# f28004x_gpio_ctrl_regs register map
Vendor: Texas Instruments
Peripheral module from a debugger description file (folder C2000).
Address unit: 16 bits
Registers are 32-bit, read-write, no defined reset value unless marked. A register's access mark holds for its fields unless they carry their own. Offsets are as the file gives them; lines under a group give offsets from that group; [hi:lo] are bit positions; {n}, {i} and the like mark numbered series; 'fields as' and 'values as' point back to an identical list; <NAME> marks a mode.

## GPIO_CTRL_REGS — GPIO CTRL Registers
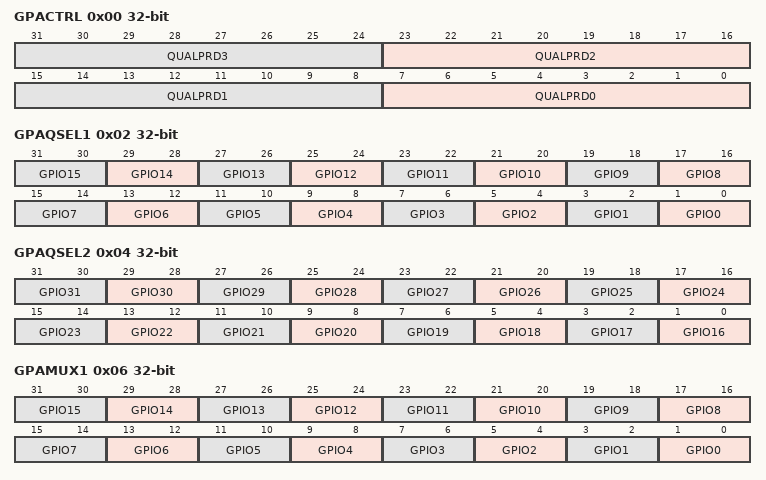
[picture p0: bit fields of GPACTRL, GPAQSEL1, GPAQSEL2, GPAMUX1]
0x00 GPACTRL — GPIO A Qualification Sampling Period (GPIO0 to GPIO31)
  [8n+7:8n] QUALPRD{n} (n=0..3) — Qualification sampling period for GPIO{8n} to GPIO{8n+7}
0x02 GPAQSEL1 — GPIO A Qualification Type (GPIO0 to GPIO15)
  [2n+1:2n] GPIO{n} (n=0..15) — Select input qualification type for GPIO{n}
0x04 GPAQSEL2 — GPIO A Qualification Type (GPIO16 to GPIO31)
  [2n-31:2n-32] GPIO{n} (n=16..31) — Select input qualification type for GPIO{n}
0x06 GPAMUX1 — GPIO A Peripheral Mux (GPIO0 to GPIO15)
  [2n+1:2n] GPIO{n} (n=0..15) — Defines pin-muxing selection for GPIO{n}
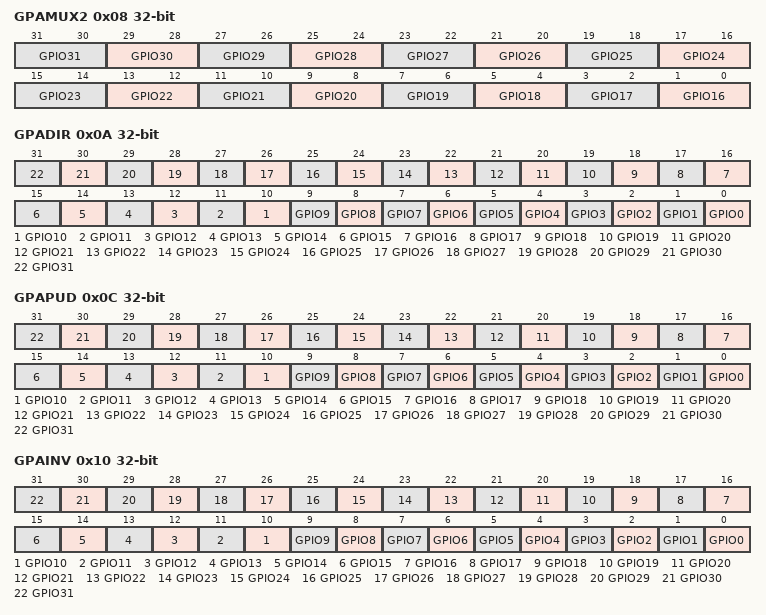
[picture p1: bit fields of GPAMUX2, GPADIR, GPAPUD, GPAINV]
0x08 GPAMUX2 — GPIO A Peripheral Mux (GPIO16 to GPIO31)
  [2n-31:2n-32] GPIO{n} (n=16..31) — Defines pin-muxing selection for GPIO{n}
0x0A GPADIR — GPIO A Direction (GPIO0 to GPIO31)
  [n] GPIO{n} (n=0..31) — Defines direction for this pin in GPIO mode
0x0C GPAPUD — GPIO A Pull-Up Disable (GPIO0 to GPIO31)
  [n] GPIO{n} (n=0..31) — Pull-Up Disable control for this pin
0x10 GPAINV — GPIO A Input Inversion (GPIO0 to GPIO31)
  [n] GPIO{n} (n=0..31) — Input inversion control for this pin
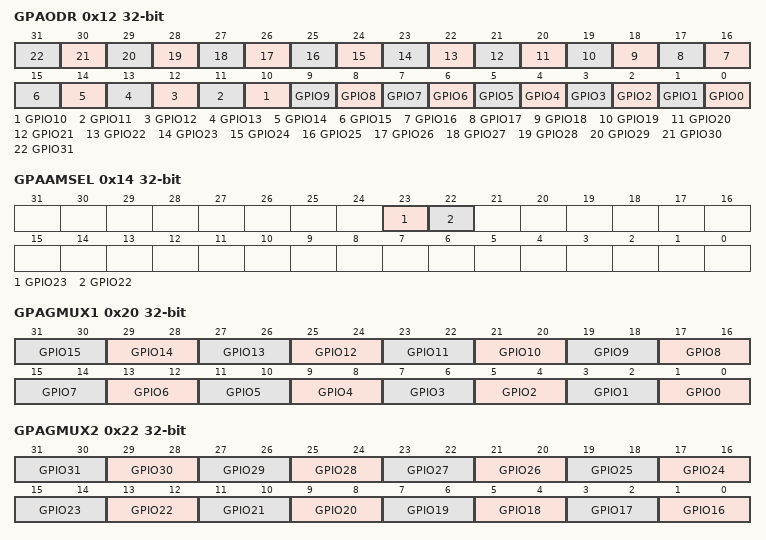
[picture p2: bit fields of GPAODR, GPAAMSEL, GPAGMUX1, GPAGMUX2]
0x12 GPAODR — GPIO A Open Drain Output Mode (GPIO0 to GPIO31)
  [n] GPIO{n} (n=0..31) — Output Open-Drain control for this pin
0x14 GPAAMSEL — GPIO A Analog Mode Select (GPIO0 to GPIO31)
  [23] GPIO23 — Analog Mode select for this pin
  [22] GPIO22 — Analog Mode select for this pin
0x20 GPAGMUX1 — GPIO A Peripheral Group Mux (GPIO0 to GPIO15)
  fields as GPAMUX1
0x22 GPAGMUX2 — GPIO A Peripheral Group Mux (GPIO16 to GPIO31)
  fields as GPAMUX2
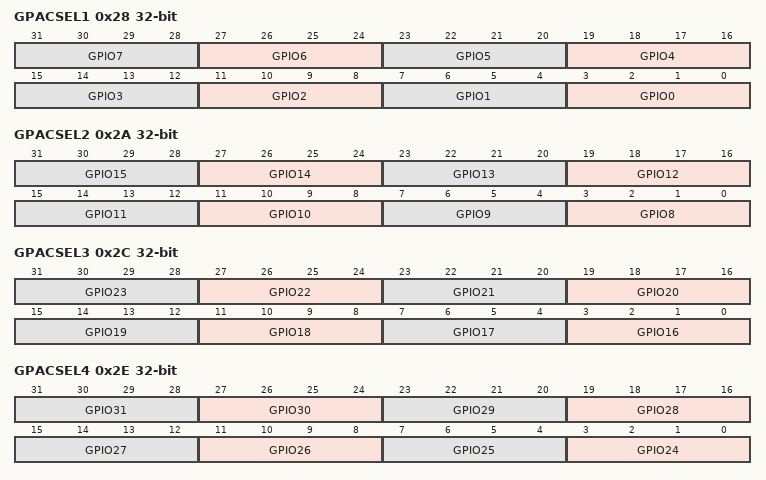
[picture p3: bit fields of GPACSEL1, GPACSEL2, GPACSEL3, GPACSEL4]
0x28 GPACSEL1 — GPIO A Master Core Select (GPIO0 to GPIO7)
  [4n+3:4n] GPIO{n} (n=0..7) — GPIO{n} Master CPU Select
0x2A GPACSEL2 — GPIO A Master Core Select (GPIO8 to GPIO15)
  [4n-29:4n-32] GPIO{n} (n=8..15) — GPIO{n} Master CPU Select
0x2C GPACSEL3 — GPIO A Master Core Select (GPIO16 to GPIO23)
  [4n-61:4n-64] GPIO{n} (n=16..23) — GPIO{n} Master CPU Select
0x2E GPACSEL4 — GPIO A Master Core Select (GPIO24 to GPIO31)
  [4n-93:4n-96] GPIO{n} (n=24..31) — GPIO{n} Master CPU Select
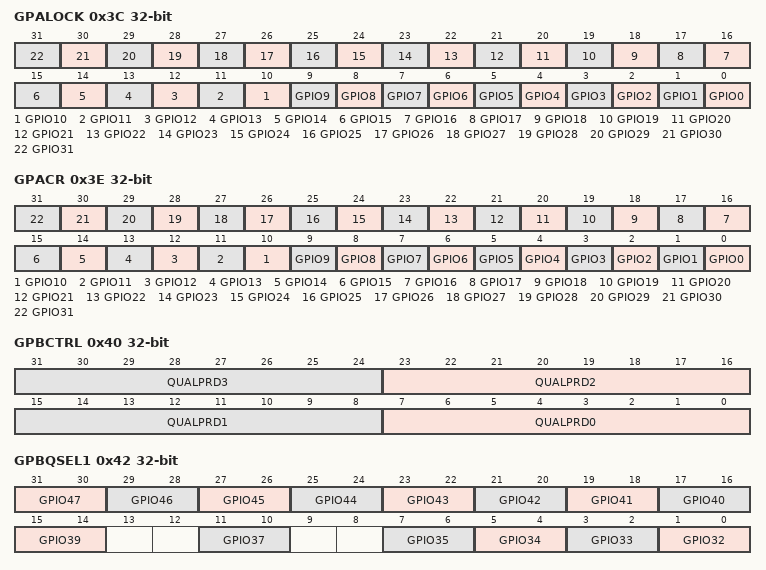
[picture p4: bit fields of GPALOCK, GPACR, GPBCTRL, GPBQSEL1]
0x3C GPALOCK — GPIO A Lock Register (GPIO0 to GPIO31)
  [n] GPIO{n} (n=0..31) — Configuration Lock bit for this pin
0x3E GPACR access not given — GPIO A Lock Commit Register (GPIO0 to GPIO31)
  [n] GPIO{n} (n=0..31) — Configuration lock commit bit for this pin (access R/SOnce)
0x40 GPBCTRL — GPIO B Qualification Sampling Period (GPIO32 to GPIO63)
  [8n+7:8n] QUALPRD{n} (n=0..3) — Qualification sampling period for GPIO{8n+32} to GPIO{8n+39}
0x42 GPBQSEL1 — GPIO B Qualification Type (GPIO32 to GPIO47)
  [2n-63:2n-64] GPIO{n} (n=39..47) — Select input qualification type for GPIO{n}
  [11:10] GPIO37 — Select input qualification type for GPIO37
  [2n-63:2n-64] GPIO{n} (n=32..35) — Select input qualification type for GPIO{n}
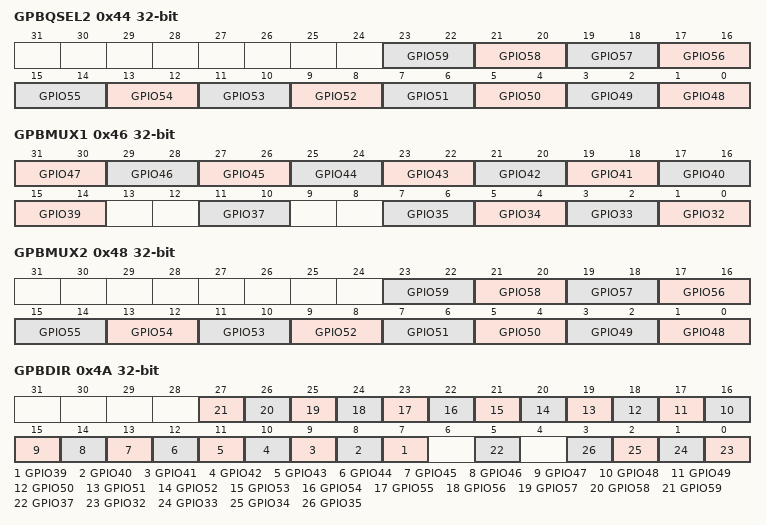
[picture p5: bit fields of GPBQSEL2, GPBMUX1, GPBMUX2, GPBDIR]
0x44 GPBQSEL2 — GPIO B Qualification Type (GPIO48 to GPIO63)
  [2n-95:2n-96] GPIO{n} (n=48..59) — Select input qualification type for GPIO{n}
0x46 GPBMUX1 — GPIO B Peripheral Mux (GPIO32 to GPIO47)
  [2n-63:2n-64] GPIO{n} (n=39..47) — Defines pin-muxing selection for GPIO{n}
  [11:10] GPIO37 — Defines pin-muxing selection for GPIO37
  [2n-63:2n-64] GPIO{n} (n=32..35) — Defines pin-muxing selection for GPIO{n}
0x48 GPBMUX2 — GPIO B Peripheral Mux (GPIO48 to GPIO63)
  [2n-95:2n-96] GPIO{n} (n=48..59) — Defines pin-muxing selection for GPIO{n}
0x4A GPBDIR — GPIO B Direction (GPIO32 to GPIO63)
  [n-32] GPIO{n} (n=39..59) — Defines direction for this pin in GPIO mode
  [5] GPIO37 — Defines direction for this pin in GPIO mode
  [n-32] GPIO{n} (n=32..35) — Defines direction for this pin in GPIO mode
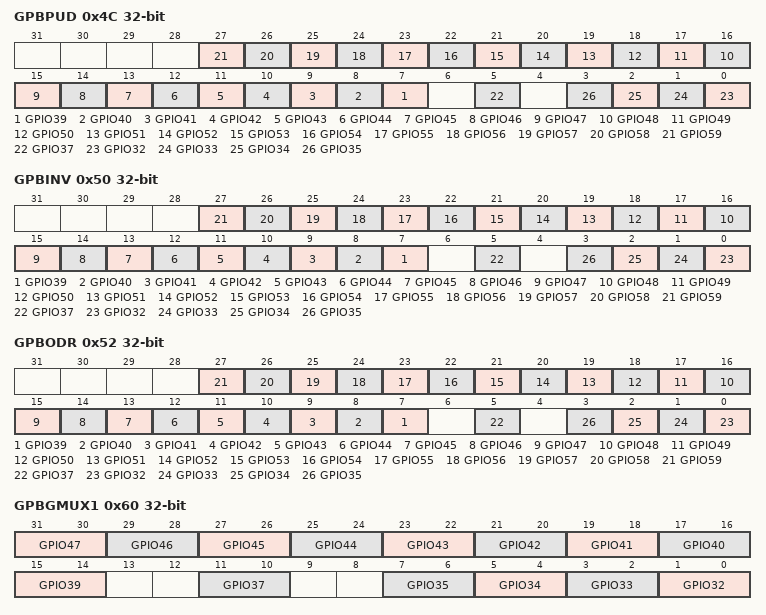
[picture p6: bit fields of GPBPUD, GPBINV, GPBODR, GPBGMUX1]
0x4C GPBPUD — GPIO B Pull-Up Disable (GPIO32 to GPIO63)
  [n-32] GPIO{n} (n=39..59) — Pull-Up Disable control for this pin
  [5] GPIO37 — Pull-Up Disable control for this pin
  [n-32] GPIO{n} (n=32..35) — Pull-Up Disable control for this pin
0x50 GPBINV — GPIO B Input Inversion (GPIO32 to GPIO63)
  [n-32] GPIO{n} (n=39..59) — Input inversion control for this pin
  [5] GPIO37 — Input inversion control for this pin
  [n-32] GPIO{n} (n=32..35) — Input inversion control for this pin
0x52 GPBODR — GPIO B Open Drain Output Mode (GPIO32 to GPIO63)
  [n-32] GPIO{n} (n=39..59) — Output Open-Drain control for this pin
  [5] GPIO37 — Output Open-Drain control for this pin
  [n-32] GPIO{n} (n=32..35) — Output Open-Drain control for this pin
0x60 GPBGMUX1 — GPIO B Peripheral Group Mux (GPIO32 to GPIO47)
  fields as GPBMUX1
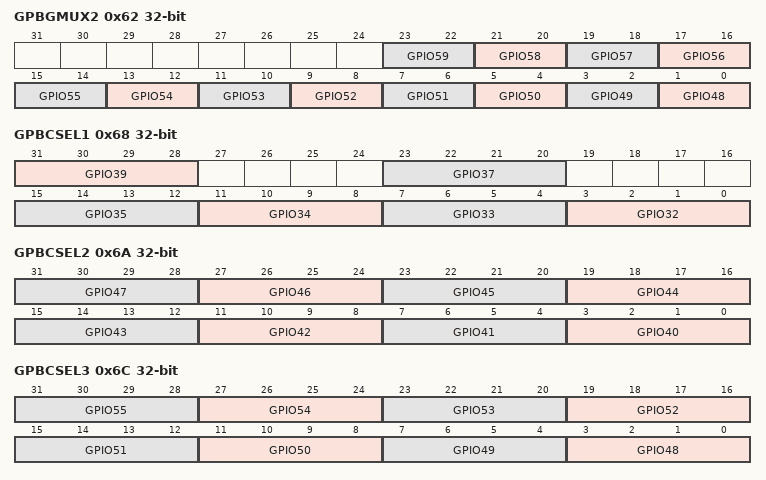
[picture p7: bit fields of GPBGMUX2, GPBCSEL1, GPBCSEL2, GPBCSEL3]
0x62 GPBGMUX2 — GPIO B Peripheral Group Mux (GPIO48 to GPIO63)
  fields as GPBMUX2
0x68 GPBCSEL1 — GPIO B Master Core Select (GPIO32 to GPIO39)
  [31:28] GPIO39 — GPIO39 Master CPU Select
  [23:20] GPIO37 — GPIO37 Master CPU Select
  [4n-125:4n-128] GPIO{n} (n=32..35) — GPIO{n} Master CPU Select
0x6A GPBCSEL2 — GPIO B Master Core Select (GPIO40 to GPIO47)
  [4n-157:4n-160] GPIO{n} (n=40..47) — GPIO{n} Master CPU Select
0x6C GPBCSEL3 — GPIO B Master Core Select (GPIO48 to GPIO55)
  [4n-189:4n-192] GPIO{n} (n=48..55) — GPIO{n} Master CPU Select
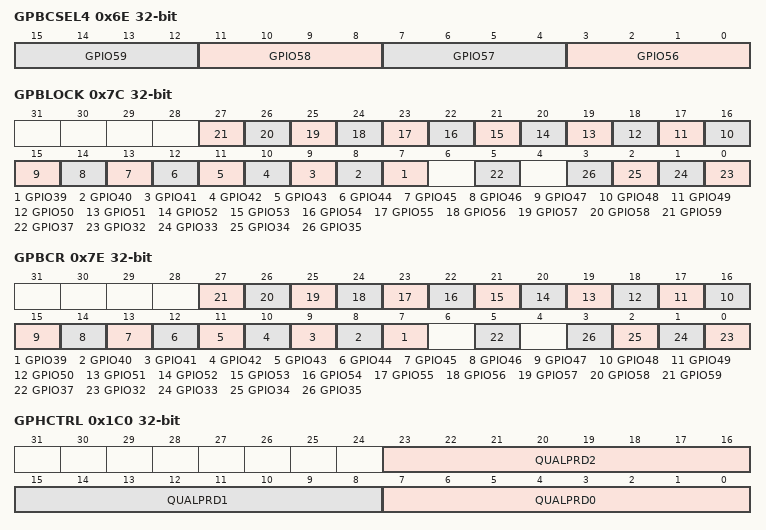
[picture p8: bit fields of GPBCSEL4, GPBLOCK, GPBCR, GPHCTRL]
0x6E GPBCSEL4 — GPIO B Master Core Select (GPIO56 to GPIO63)
  [4n-221:4n-224] GPIO{n} (n=56..59) — GPIO{n} Master CPU Select
0x7C GPBLOCK — GPIO B Lock Register (GPIO32 to GPIO63)
  [n-32] GPIO{n} (n=39..59) — Configuration Lock bit for this pin
  [5] GPIO37 — Configuration Lock bit for this pin
  [n-32] GPIO{n} (n=32..35) — Configuration Lock bit for this pin
0x7E GPBCR access not given — GPIO B Lock Commit Register (GPIO32 to GPIO63)
  [n-32] GPIO{n} (n=39..59) — Configuration lock commit bit for this pin (access R/SOnce)
  [5] GPIO37 — Configuration lock commit bit for this pin (access R/SOnce)
  [n-32] GPIO{n} (n=32..35) — Configuration lock commit bit for this pin (access R/SOnce)
0x1C0 GPHCTRL — GPIO H Qualification Sampling Period (GPIO224 to GPIO255)
  [23:16] QUALPRD2 — Qualification sampling period for GPIO240 to GPIO247
  [15:8] QUALPRD1 — Qualification sampling period for GPIO232 to GPIO239
  [7:0] QUALPRD0 — Qualification sampling period for GPIO224 to GPIO231
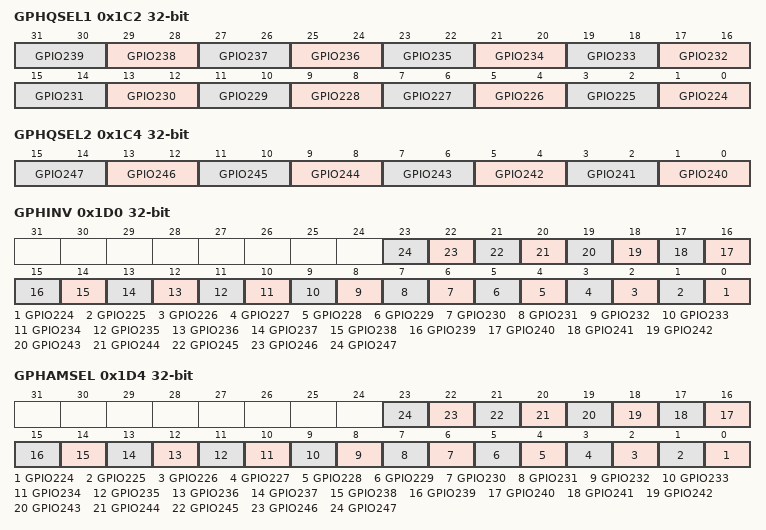
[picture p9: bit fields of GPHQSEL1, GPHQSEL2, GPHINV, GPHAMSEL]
0x1C2 GPHQSEL1 — GPIO H Qualification Type (GPIO224 to GPIO239)
  [2n-447:2n-448] GPIO{n} (n=224..239) — Select input qualification type for this GPIO Pin
0x1C4 GPHQSEL2 — GPIO H Qualification Type (GPIO240 to GPIO255)
  [2n-479:2n-480] GPIO{n} (n=240..247) — Select input qualification type for this GPIO Pin
0x1D0 GPHINV — GPIO H Input Inversion (GPIO224 to GPIO255)
  [n-224] GPIO{n} (n=224..247) — Input inversion control for this pin
0x1D4 GPHAMSEL — GPIO H Analog Mode Select (GPIO224 to GPIO255)
  [n-224] GPIO{n} (n=224..247) — Analog Mode select for this pin
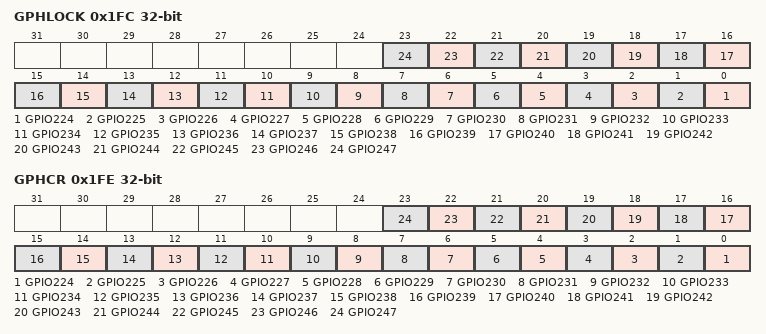
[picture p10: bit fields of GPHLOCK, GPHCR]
0x1FC GPHLOCK — GPIO H Lock Register (GPIO224 to GPIO255)
  [n-224] GPIO{n} (n=224..247) — Configuration Lock bit for this pin
0x1FE GPHCR access not given — GPIO H Lock Commit Register (GPIO224 to GPIO255)
  [n-224] GPIO{n} (n=224..247) — Configuration lock commit bit for this pin (access R/SOnce)
